# DemoM0 register map
File version: 0.0.1
Synthetic Cortex-M0 example; not a real chip.
CPU: CM0 r0p0, little endian, no MPU, no FPU, 2 interrupt priority bits
Registers are 32-bit, read-write, reset 0x0 unless marked. A register's access mark holds for its fields unless they carry their own. Offsets are from the block's base; lines under a group give offsets from that group; [hi:lo] are bit positions; {n}, {i} and the like mark numbered series; 'fields as' and 'values as' point back to an identical list; <NAME> marks a mode.

## Memory map
0x40000000 DEMO size 0x8 — Synthetic peripheral for conversion testing.

## Interrupts
0 DEMO — Synthetic external interrupt zero.

## DEMO — Synthetic peripheral for conversion testing.
Base 0x40000000
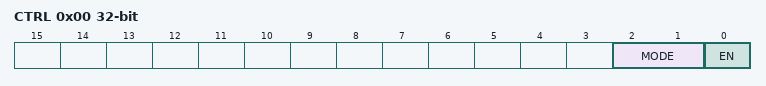
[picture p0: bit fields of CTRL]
0x00 CTRL — Synthetic control register.
  [2:1] MODE — Synthetic mode selection.
    0=MODE_A (Synthetic mode A.); 1=MODE_B (Synthetic mode B.); 2=MODE_C (Synthetic mode C.); 3=MODE_D (Synthetic mode D.)
  [0] EN — Synthetic enable bit.
    0=DISABLED; 1=ENABLED
0x04 STATUS — Synthetic status register with a W1C flag.
  [0] FLAG write-1-clears — Write one to clear this synthetic flag.
